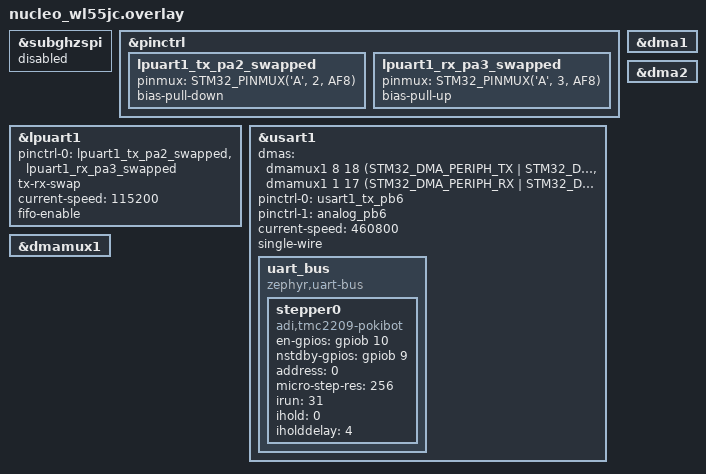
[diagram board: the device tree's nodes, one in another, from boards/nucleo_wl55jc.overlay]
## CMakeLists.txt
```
cmake_minimum_required(VERSION 3.20.0)

find_package(Zephyr REQUIRED HINTS $ENV{ZEPHYR_BASE})
project(test_mks-can)

target_include_directories(app PRIVATE src)

file(GLOB_RECURSE APP_SOURCES src/*.c)

target_sources(app PRIVATE ${APP_SOURCES})

# Quick hack for Clion to include all zephyr workspace files in the project file tree view.
include_directories(${ZEPHYR_BASE}/..)
```

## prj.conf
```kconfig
# SERIAL
CONFIG_SERIAL=y
CONFIG_LOG=y
CONFIG_UART_INTERRUPT_DRIVEN=y
#CONFIG_DMA=y
CONFIG_UART_ASYNC_API=y

CONFIG_LOG_MODE_DEFERRED=y
# CONFIG_LOG_MODE_IMMEDIATE=y
CONFIG_LOG_BACKEND_SHOW_COLOR=y
CONFIG_LOG_DEFAULT_LEVEL=3
CONFIG_LOG_BUFFER_SIZE=8192

CONFIG_MAIN_STACK_SIZE=4096

#CONFIG_POKSTEPPER=y

CONFIG_CAN=y
CONFIG_CAN_FD_MODE=y
CONFIG_CAN_STM32H7_FDCAN=y

CONFIG_CBPRINTF_COMPLETE=y
CONFIG_CBPRINTF_FP_SUPPORT=y
```

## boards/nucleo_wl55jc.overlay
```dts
&subghzspi {
	status = "disabled";
};

&pinctrl {
	/omit-if-no-ref/ lpuart1_tx_pa2_swapped: lpuart1_tx_pa2_swapped {
		pinmux = <STM32_PINMUX('A', 2, AF8)>;
		bias-pull-down;
	};

	/omit-if-no-ref/ lpuart1_rx_pa3_swapped: lpuart1_rx_pa3_swapped {
		pinmux = <STM32_PINMUX('A', 3, AF8)>;
		bias-pull-up;
	};
};


&lpuart1 {
	pinctrl-0 = <&lpuart1_tx_pa2_swapped &lpuart1_rx_pa3_swapped>;
	pinctrl-names = "default";
	tx-rx-swap;
	current-speed = <115200>;
	fifo-enable;
	status = "okay";
};

&usart1 {
	status = "okay";
	dmas = <&dmamux1 8 18 (STM32_DMA_PERIPH_TX | STM32_DMA_PRIORITY_HIGH)
		&dmamux1 1 17 (STM32_DMA_PERIPH_RX | STM32_DMA_PRIORITY_HIGH)>;
	dma-names = "tx", "rx";
	pinctrl-0 = <&usart1_tx_pb6>;
	pinctrl-1 = <&analog_pb6>;
	pinctrl-names = "default", "sleep";
	current-speed = <460800>;
	single-wire;

	uart_bus {
		compatible = "zephyr,uart-bus";
		status = "okay";

		stepper0:stepper0 {
			status = "okay";
			compatible = "adi,tmc2209-pokibot";
			en-gpios = <&gpiob 10 GPIO_ACTIVE_HIGH>;
			nstdby-gpios = <&gpiob 9 GPIO_ACTIVE_HIGH>;
			address = <0>;
			micro-step-res = <256>;
			irun = <31>;
			ihold = <0>;
			iholddelay = <4>;
		};
	};
};

&dma1 {
	status = "okay";
};

&dma2 {
	status = "okay";
};

&dmamux1 {
	status = "okay";
};
```

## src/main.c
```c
#include <zephyr/kernel.h>
#include <zephyr/logging/log.h>


LOG_MODULE_REGISTER(main);

const struct device *const can_dev = DEVICE_DT_GET(DT_CHOSEN(zephyr_canbus));

int main(void)
{

    LOG_INF("trying can dev");
    if (!device_is_ready(can_dev)) {
        LOG_ERR("CAN: Device %s not ready.\n", can_dev->name);
        return 0;
    }
    LOG_INF("CAn dev ok");

    while (1) {
        k_sleep(K_MSEC(500));

    }
}
```
